# MDR1986VE4 register map
Vendor: Milandr; Series: ARMCM0; File version: 2.0
CPU: CM0 r0p0, little endian, no MPU, no FPU, 2 interrupt priority bits
Registers are 32-bit, read-write, reset 0x0 unless marked. A register's access mark holds for its fields unless they carry their own. Offsets are from the block's base; [hi:lo] are bit positions; {n}, {i} and the like mark numbered series.

## MDR_CRC_VE4 — CRC Controler
Base 0x40098000
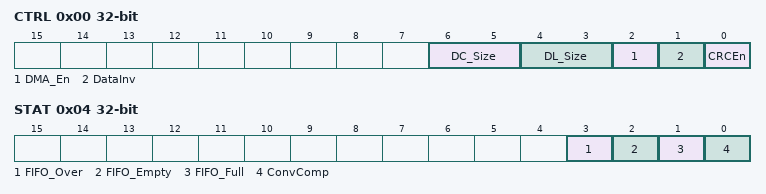
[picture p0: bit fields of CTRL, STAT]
0x00 CTRL (reset mask 0x3F) — Control register
  [6:5] DC_Size — Calculating data size
    0=Byte data word; 1=16-bit data word; 2=32-bit data word
  [4:3] DL_Size — Loading data size
    0=Byte data stream; 1=16-bit data stream; 2=32-bit data stream
  [2] DMA_En — DMA Enable
    0=Off (Disabled); 1=On (Enabled)
  [1] DataInv — Bit first selection
    0=LSB (Low bit first); 1=MSB (High bit first)
  [0] CRCEn — Enable block
    0=Disabled (Block inactive); 1=Enabled (Block active)
0x04 STAT — Status register
  [3] FIFO_Over
    0=Off (Flag Inactive); 1=On (Flag Active)
  [2] FIFO_Empty ro
    0=Off (Flag Inactive); 1=On (Flag Active)
  [1] FIFO_Full ro
    0=Off (Flag Inactive); 1=On (Flag Active)
  [0] ConvComp ro — Convertion Completed
    0=Processing (Calculation processing); 1=Completed (Calculation completed)
0x08 DATAI wo — FIFO Input
  [31:0] Value — Data Value
0x0C CRC_VAL — CRC result
  [15:0] CRC_Out — Result and Start Value
0x10 CRC_POL — CRC Polinom select
  [16:0] CRC_POL — Select polinom bits

## MDR_SSP1 — Synchronous Serial Port
Base 0x40000000
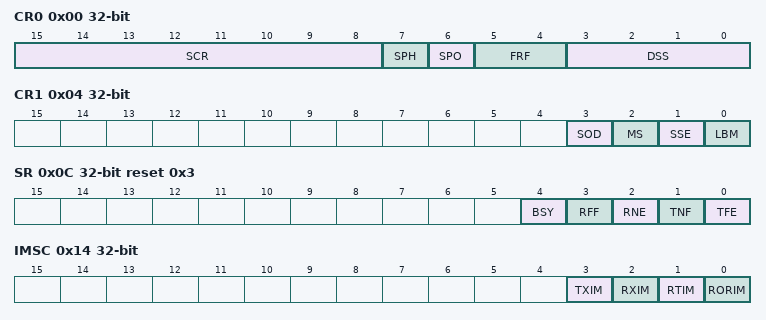
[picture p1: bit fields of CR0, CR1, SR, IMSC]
0x00 CR0 — Control Register 0
  [15:8] SCR — Signal CLock Rate
  [7] SPH — SPI Capture Clock Phase
    0=Leading (Capture data on leading edge); 1=Trailing (Capture data on trailing edge)
  [6] SPO — SPI Clock Polarity
    0=Idle_Low (Idle state is Low); 1=Idle_High (Idle state is High)
  [5:4] FRF — Frame Format
    0=SPI (Motorola SPI protocol); 1=SSI (Texas Instruments SSI protocol); 2=Microwire (National Semiconductor Microwire protocol)
  [3:0] DSS — Data Size Select
    {v}=bits_{v+1} (Word of {v+1} bits) (v=3..15)
0x04 CR1 — Control Register 1
  [3] SOD — Slave mode Output Disable
    0=SlaveTxEna (Slave mode transmit enable); 1=SlaveTxDis (Slave mode transmit disable)
  [2] MS — Master or Slave mode
    0=Master Mode; 1=Slave Mode
  [1] SSE — Synchronous Serial Enable
    0=Off (SSP Disable); 1=On (SSP Enable)
  [0] LBM — Loop Back Mode
    0=Normal operation; 1=LoopBack (TX send to RX test mode)
0x08 DR — FIFO_Rx and FIFO_Tx access
  [15:0] Data — Data value
0x0C SR ro reset 0x3 — Status Register
  [4] BSY — Transfer in progress
    0=Idle (FIFO_RX is Not Full); 1=Busy (Transfering)
  [3] RFF — FIFO_RX is Full
    0=RX_NotFull (FIFO_RX is Not Full); 1=RX_Full (FIFO_RX is Full)
  [2] RNE — FIFO_RX is Not Empty
    0=RX_NotEmpty (FIFO_RX is Empty); 1=RX_Empty (FIFO_RX is Not Empty)
  [1] TNF — FIFO_TX is Not Full
    0=TX_Full (FIFO_TX is Full); 1=TX_NotFull (FIFO_TX is Not Full)
  [0] TFE — FIFO_TX is Empty
    0=TX_NotEmpty (FIFO_TX is Not Empty); 1=TX_Empty (FIFO_TX is Empty)
0x10 CPSR — Clock Prescaller Register
  [7:0] CPSDVSR — Clock Prescaller
0x14 IMSC — IRQ Mask Set-Clear
  [3] TXIM — Enable IQR on FIFO_TX le 4 words
    0=NoEvent (Flag Inactive); 1=TX_HalfEmpty (Flag Active)
  [2] RXIM — Enable IQR on FIFO_RX ge 4 words
    0=NoEvent (Flag Inactive); 1=RX_HalfFull (Flag Active)
  [1] RTIM — Enable IQR on RX timeout for 32bits
    0=NoEvent (Flag Inactive); 1=RX_Timeout (Flag Active)
  [0] RORIM — Enable IRQ on FIFO_RX overrun
    0=NoEvent (Flag Inactive); 1=RX_Overrun (Flag Active)
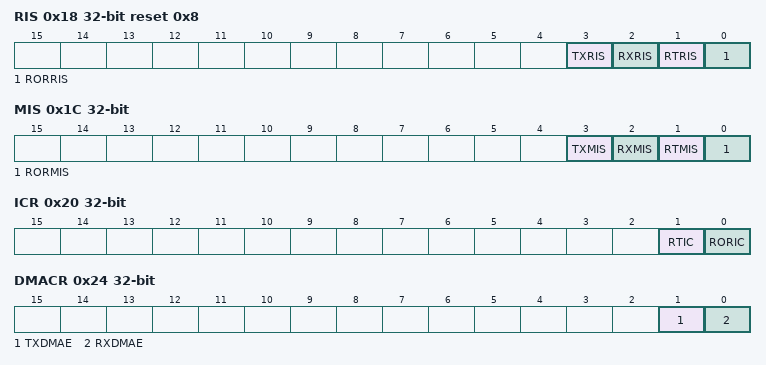
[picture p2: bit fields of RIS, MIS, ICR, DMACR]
0x18 RIS ro reset 0x8 — Raw Interupt Status
  [3] TXRIS — FIFO_TX le words
    0=NoEvent (Flag Inactive); 1=TX_HalfEmpty (Flag Active)
  [2] RXRIS — FIFO_RX gt words
    0=NoEvent (Flag Inactive); 1=RX_HalfFull (Flag Active)
  [1] RTRIS — RX timeout for 32bits
    0=NoEvent (Flag Inactive); 1=RX_Timeout (Flag Active)
  [0] RORRIS — FIFO_RX is overrun
    0=NoEvent (Flag Inactive); 1=RX_Overrun (Flag Active)
0x1C MIS ro — Masked Interupt Status
  [3] TXMIS — FIFO_TX le 4 words
    0=NoEvent (Flag Inactive); 1=TX_HalfEmpty (Flag Active)
  [2] RXMIS — FIFO_RX ge 4 words
    0=NoEvent (Flag Inactive); 1=RX_HalfFull (Flag Active)
  [1] RTMIS — RX timeout for 32bits
    0=NoEvent (Flag Inactive); 1=RX_Timeout (Flag Active)
  [0] RORMIS — FIFO_RX is overrun
    0=NoEvent (Flag Inactive); 1=RX_Overrun (Flag Active)
0x20 ICR wo — Interupt Clear Register
  [1] RTIC — Clear RX timeout flag
    0=Inactive (No action); 1=Clear Flag
  [0] RORIC — Clear FIFO_RX overrun flag
    0=Inactive (No action); 1=Clear Flag
0x24 DMACR — DMA Control Register
  [1] TXDMAE — Enable DMA by FIFO_TX not Full
    0=Disable DMA; 1=Enable DMA
  [0] RXDMAE — Enable DMA by FIFO_RX has data
    0=Disable DMA; 1=Enable DMA

## MDR_PORTA — GPIO Port Control
Base 0x40080000
Same registers: MDR_PORTB 0x40088000, MDR_PORTC 0x40090000
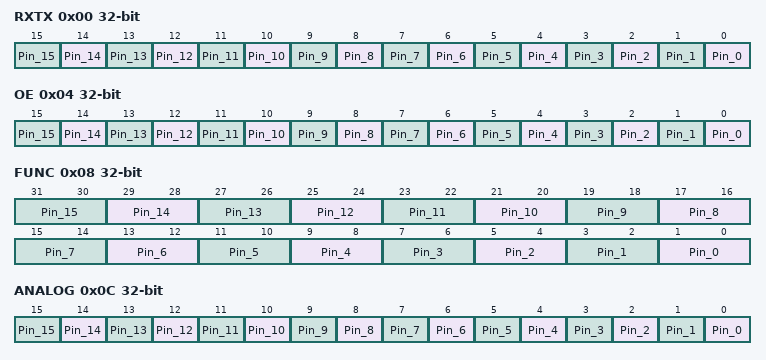
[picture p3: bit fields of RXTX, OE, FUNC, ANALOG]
0x00 RXTX (reset mask 0xFFFF) — GPIO Pin Data
  [n] Pin_{n} (n=0..15) — Pin data value
    0=Low (LOW Level Voltage); 1=HIGH Level Voltage
0x04 OE (reset mask 0xFFFF) — Output Enable Control
  [n] Pin_{n} (n=0..15) — Pin data direction
    0=IN (Input pin); 1=OUT (Output pin)
0x08 FUNC — Pin Functions in Digital mode
  [2n+1:2n] Pin_{n} (n=0..15) — Pin Digital Function
    0=Port (RXTX defined pin); 1=Main Periph defined pin; 2=Alter Periph defined pin; 3=Override Periph defined pin
0x0C ANALOG (reset mask 0xFFFF) — Enable Digital Mode Control
  [n] Pin_{n} (n=0..15) — Enable Digital mode
    0=Analog (Pin works with Analog signal); 1=Digital (Pin works with Digital signal)
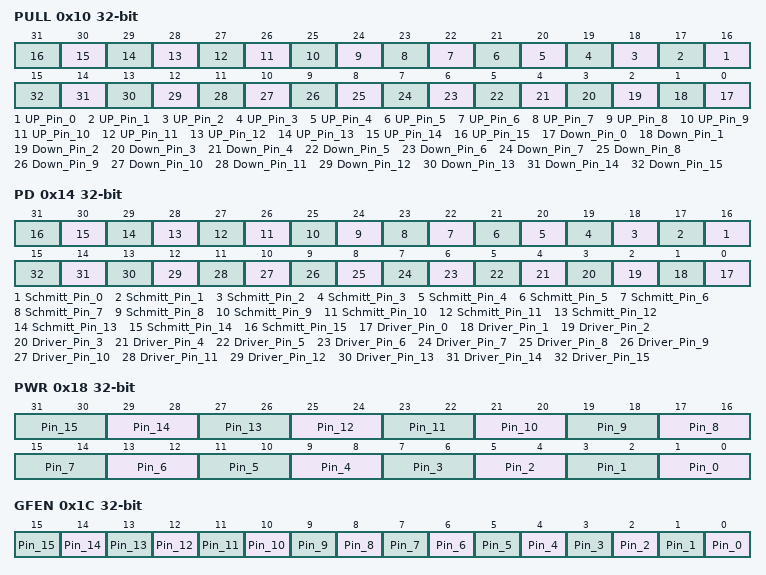
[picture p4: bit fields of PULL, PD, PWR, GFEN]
0x10 PULL — PULL Up and Down Control
  [n+16] UP_Pin_{n} (n=0..15) — Pull Up Enable
    0=Off (No pull selected); 1=UP (Pin pulled up to Ucc)
  [n] Down_Pin_{n} (n=0..15) — Pull Down Enable
    0=Off (No pull selected); 1=DOWN (Pin pulled down to GND)
0x14 PD — Otput Driver Mode
  [n+16] Schmitt_Pin_{n} (n=0..15) — Schmitt trigger enable
    0=Off (Schmitt 200mv); 1=On (Schmitt 400mv)
  [n] Driver_Pin_{n} (n=0..15) — Driver mode for pin
    0=Driver (Pull-Push driver); 1=OpenDrain (Work with line pulled up to Ucc)
0x18 PWR — Output voltage switch rate
  [2n+1:2n] Pin_{n} (n=0..15) — Voltage levels switch rate
    0=Off (Level switch disabled); 1=Slow (Levels switch rate about 100ns); 2=Fast (Levels switch rate about 20ns); 3=MaxFast (Levels switch rate about 10ns)
0x1C GFEN (reset mask 0xFFFF) — Input pulses filter
  [n] Pin_{n} (n=0..15) — Filter for pin
    0=Off (Filter Off); 1=On (Filter pulses less then 10 ns)
